# Port_1_2_3 register map
Vendor: Texas Instruments
Peripheral module from a debugger description file (folder msp430).
Registers are 8-bit, read-write, reset 0x0 unless marked. A register's access mark holds for its fields unless they carry their own. Offsets are as the file gives them; lines under a group give offsets from that group; [hi:lo] are bit positions; {n}, {i} and the like mark numbered series; 'fields as' and 'values as' point back to an identical list; <NAME> marks a mode.

## Port_1/2
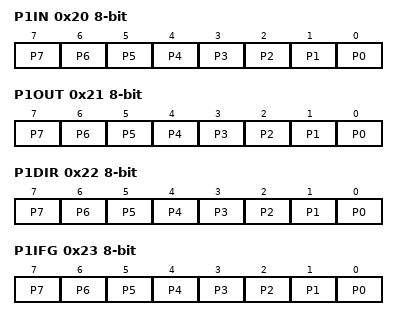
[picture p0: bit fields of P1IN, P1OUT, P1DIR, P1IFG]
0x20 P1IN — Port 1 Input
  [n] P{n} (n=0..7)
0x21 P1OUT — Port 1 Output
  [n] P{n} (n=0..7)
0x22 P1DIR — Port 1 Direction
  [n] P{n} (n=0..7)
0x23 P1IFG — Port 1 Interrupt Flag
  [n] P{n} (n=0..7)
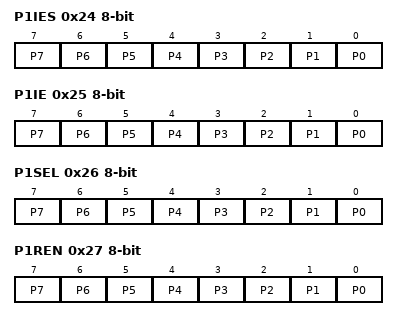
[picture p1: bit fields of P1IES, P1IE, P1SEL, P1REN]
0x24 P1IES — Port 1 Interrupt Edge Select
  [n] P{n} (n=0..7)
0x25 P1IE — Port 1 Interrupt Enable
  [n] P{n} (n=0..7)
0x26 P1SEL — Port 1 Selection
  [n] P{n} (n=0..7)
0x27 P1REN — Port 1 Resistor Enable
  [n] P{n} (n=0..7)
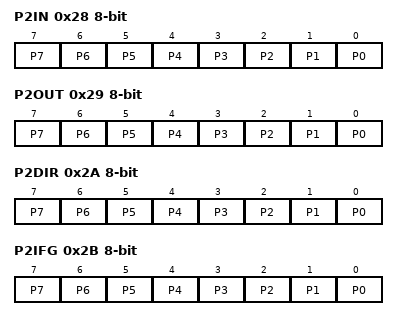
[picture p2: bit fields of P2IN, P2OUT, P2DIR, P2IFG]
0x28 P2IN — Port 2 Input
  [n] P{n} (n=0..7)
0x29 P2OUT — Port 2 Output
  [n] P{n} (n=0..7)
0x2A P2DIR — Port 2 Direction
  [n] P{n} (n=0..7)
0x2B P2IFG — Port 2 Interrupt Flag
  [n] P{n} (n=0..7)
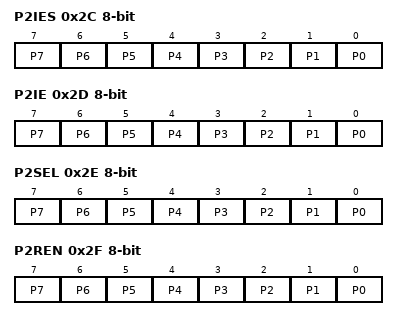
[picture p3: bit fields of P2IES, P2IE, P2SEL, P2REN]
0x2C P2IES — Port 2 Interrupt Edge Select
  [n] P{n} (n=0..7)
0x2D P2IE — Port 2 Interrupt Enable
  [n] P{n} (n=0..7)
0x2E P2SEL — Port 2 Selection
  [n] P{n} (n=0..7)
0x2F P2REN — Port 2 Resistor Enable
  [n] P{n} (n=0..7)
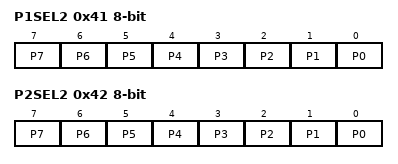
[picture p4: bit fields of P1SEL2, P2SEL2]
0x41 P1SEL2 — Port 1 Selection 2
  [n] P{n} (n=0..7)
0x42 P2SEL2 — Port 2 Selection 2
  [n] P{n} (n=0..7)
